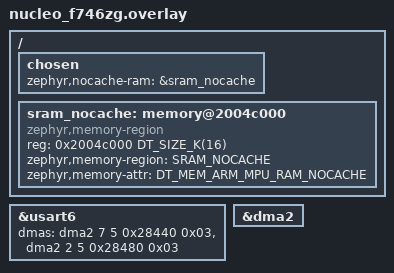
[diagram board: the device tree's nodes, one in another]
/*
 * Copyright (c) 2024 Abderrahmane JARMOUNI
 *
 * SPDX-License-Identifier: Apache-2.0
 */

/ {
	chosen {
		zephyr,nocache-ram = &sram_nocache;
	};

	sram_nocache: memory@2004c000 {
		compatible = "zephyr,memory-region", "mmio-sram";
		reg = <0x2004c000 DT_SIZE_K(16)>;
		zephyr,memory-region = "SRAM_NOCACHE";
		zephyr,memory-attr = <DT_MEM_ARM_MPU_RAM_NOCACHE>;
	};
};

dut: &usart6 {
	dmas = <&dma2 7 5 0x28440 0x03>,
		<&dma2 2 5 0x28480 0x03>;
	dma-names = "tx", "rx";
	status = "okay";
};

&dma2 {
	status = "okay";
};
